# nrf52840 register map
Vendor: Nordic Semiconductor; Series: nrf52; File version: 1
CPU: CM4 r0p1, little endian, MPU, FPU, 3 interrupt priority bits
Registers are 32-bit, read-write, reset 0x0 unless marked. A register's access mark holds for its fields unless they carry their own. Offsets are from the block's base; [hi:lo] are bit positions.

## AAR — Accelerated Address Resolver
Base 0x4000F000
0x00 TASKS_START wo — Start resolving addresses based on IRKs specified in the IRK data structure
  [0] TASKS_START
0x08 TASKS_STOP wo — Stop resolving addresses
  [0] TASKS_STOP
0x100 EVENTS_END — Address resolution procedure complete
  [0] EVENTS_END
0x104 EVENTS_RESOLVED — Address resolved
  [0] EVENTS_RESOLVED
0x108 EVENTS_NOTRESOLVED — Address not resolved
  [0] EVENTS_NOTRESOLVED
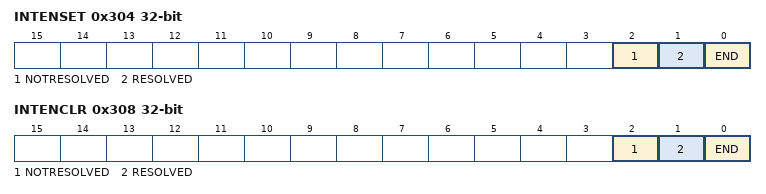
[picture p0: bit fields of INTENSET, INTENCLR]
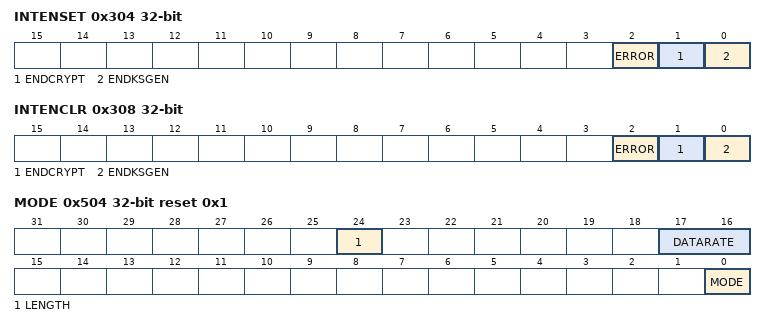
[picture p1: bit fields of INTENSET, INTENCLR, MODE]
0x304 INTENSET — Enable interrupt
  [all] fields
    on read: 0=Disabled (Read: Disabled); 1=Enabled (Read: Enabled) | on write: 1=Set (Enable)
  [2] NOTRESOLVED — Write '1' to enable interrupt for NOTRESOLVED event
  [1] RESOLVED — Write '1' to enable interrupt for RESOLVED event
  [0] END — Write '1' to enable interrupt for END event
0x308 INTENCLR — Disable interrupt
  [all] fields
    on read: 0=Disabled (Read: Disabled); 1=Enabled (Read: Enabled) | on write: 1=Clear (Disable)
  [2] NOTRESOLVED — Write '1' to disable interrupt for NOTRESOLVED event
  [1] RESOLVED — Write '1' to disable interrupt for RESOLVED event
  [0] END — Write '1' to disable interrupt for END event
0x400 STATUS ro — Resolution status
  [3:0] STATUS — The IRK that was used last time an address was resolved
0x500 ENABLE — Enable AAR
  [1:0] ENABLE — Enable or disable AAR
    0=Disabled; 3=Enabled
0x504 NIRK reset 0x1 — Number of IRKs
  [4:0] NIRK — Number of Identity root keys available in the IRK data structure
0x508 IRKPTR — Pointer to IRK data structure
  [31:0] IRKPTR — Pointer to the IRK data structure
0x510 ADDRPTR — Pointer to the resolvable address
  [31:0] ADDRPTR — Pointer to the resolvable address (6-bytes)
0x514 SCRATCHPTR — Pointer to data area used for temporary storage
  [31:0] SCRATCHPTR — Pointer to a scratch data area used for temporary storage during resolution.A space of minimum 3 bytes must be reserved.

## CCM — AES CCM Mode Encryption
Base 0x4000F000; alternate view of AAR
0x00 TASKS_KSGEN wo — Start generation of key-stream. This operation will stop by itself when completed.
  [0] TASKS_KSGEN
0x04 TASKS_CRYPT wo — Start encryption/decryption. This operation will stop by itself when completed.
  [0] TASKS_CRYPT
0x08 TASKS_STOP wo — Stop encryption/decryption
  [0] TASKS_STOP
0x0C TASKS_RATEOVERRIDE wo — Override DATARATE setting in MODE register with the contents of the RATEOVERRIDE register for any ongoing encryption/decryption
  [0] TASKS_RATEOVERRIDE
0x100 EVENTS_ENDKSGEN — Key-stream generation complete
  [0] EVENTS_ENDKSGEN
0x104 EVENTS_ENDCRYPT — Encrypt/decrypt complete
  [0] EVENTS_ENDCRYPT
0x108 EVENTS_ERROR — Deprecated register - CCM error event
  [0] EVENTS_ERROR
0x200 SHORTS — Shortcut register
  [0] ENDKSGEN_CRYPT — Shortcut between ENDKSGEN event and CRYPT task
    0=Disabled (Disable shortcut); 1=Enabled (Enable shortcut)
0x304 INTENSET — Enable interrupt
  [all] fields
    on read: 0=Disabled (Read: Disabled); 1=Enabled (Read: Enabled) | on write: 1=Set (Enable)
  [2] ERROR — Write '1' to enable interrupt for ERROR event
  [1] ENDCRYPT — Write '1' to enable interrupt for ENDCRYPT event
  [0] ENDKSGEN — Write '1' to enable interrupt for ENDKSGEN event
0x308 INTENCLR — Disable interrupt
  [all] fields
    on read: 0=Disabled (Read: Disabled); 1=Enabled (Read: Enabled) | on write: 1=Clear (Disable)
  [2] ERROR — Write '1' to disable interrupt for ERROR event
  [1] ENDCRYPT — Write '1' to disable interrupt for ENDCRYPT event
  [0] ENDKSGEN — Write '1' to disable interrupt for ENDKSGEN event
0x400 MICSTATUS ro — MIC check result
  [0] MICSTATUS — The result of the MIC check performed during the previous decryption operation
    0=CheckFailed (MIC check failed); 1=CheckPassed (MIC check passed)
0x500 ENABLE
  [1:0] ENABLE — Enable or disable CCM
    0=Disabled; 2=Enabled
0x504 MODE reset 0x1 — Operation mode
  [24] LENGTH — Packet length configuration
    0=Default length. Effective length of LENGTH field in encrypted/decrypted packet is 5 bits. A key-stream for packet payloads up to 27 bytes will be generated.; 1=Extended length. Effective length of LENGTH field in encrypted/decrypted packet is 8 bits. A key-stream for packet payloads up to MAXPACKETSIZE bytes will be generated.
  [17:16] DATARATE — Radio data rate that the CCM shall run synchronous with
    0=1Mbit (1 Mbps); 1=2Mbit (2 Mbps); 2=125Kbps; 3=500Kbps
  [0] MODE — The mode of operation to be used. The settings in this register apply whenever either the KSGEN or CRYPT tasks are triggered.
    0=Encryption (AES CCM packet encryption mode); 1=Decryption (AES CCM packet decryption mode)
0x508 CNFPTR — Pointer to data structure holding AES key and NONCE vector
  [31:0] CNFPTR — Pointer to the data structure holding the AES key and the CCM NONCE vector (see Table 1 CCM data structure overview)
0x50C INPTR — Input pointer
0x510 OUTPTR — Output pointer
0x514 SCRATCHPTR — Pointer to data area used for temporary storage
  [31:0] SCRATCHPTR — Pointer to a scratch data area used for temporary storage during key-stream generation, MIC generation and encryption/decryption.
0x518 MAXPACKETSIZE reset 0xFB — Length of key-stream generated when MODE.LENGTH = Extended.
  [7:0] MAXPACKETSIZE — Length of key-stream generated when MODE.LENGTH = Extended. This value must be greater or equal to the subsequent packet payload to be encrypted/decrypted.
0x51C RATEOVERRIDE — Data rate override setting.
  [1:0] RATEOVERRIDE
    0=1Mbit (1 Mbps); 1=2Mbit (2 Mbps); 2=125Kbps; 3=500Kbps
